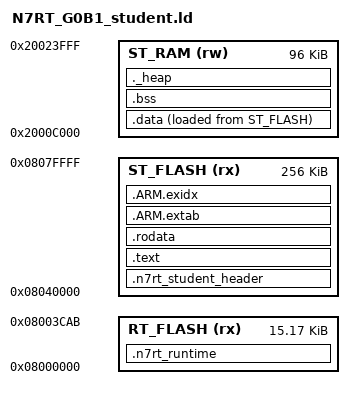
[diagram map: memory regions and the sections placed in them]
/*
 * N7RT student image, STM32G0B1RE. Generated by `stm32lab sdk` (SDK 0.1.0, runtime 0.1.0,
 * ABI 1.0). Do not edit: the runtime reads the student header at 0x08040000 and the student
 * calls the runtime through its API table at 0x08000400 (docs/can-lab-architecture.md 4.2).
 *
 *   RT_FLASH 0x08000000  precompiled runtime, exactly 15532 bytes (SHA-256 202db3fb6e7bc35d...)
 *   ST_FLASH 0x08040000  student header (64 B), student code and constants, 256 KB
 *   ST_RAM   0x2000C000  student .data / .bss / heap (8 KB), SRAM 96 KB
 * The runtime RAM (first 48 KB of SRAM) is not declared: nothing of the student image can be placed there.
 */
ENTRY(n7rt_runtime_reset)            /* 0x080004B1: the runtime Reset_Handler */
EXTERN(n7rt_student_header)

__n7rt_heap_size = 8192;

MEMORY
{
  RT_FLASH (rx) : ORIGIN = 0x08000000, LENGTH = 15532
  ST_FLASH (rx) : ORIGIN = 0x08040000, LENGTH = 256K
  ST_RAM   (rw) : ORIGIN = 0x2000C000, LENGTH = 96K
}

SECTIONS
{
  .n7rt_runtime : { KEEP(*(.n7rt_runtime)) } >RT_FLASH

  .n7rt_student_header : { KEEP(*(.n7rt_student_header)) } >ST_FLASH

  .text :
  {
    . = ALIGN(4);
    *(.text .text.*)
    *(.glue_7) *(.glue_7t) *(.vfp11_veneer) *(.v4_bx) *(.eh_frame)
    . = ALIGN(4);
  } >ST_FLASH

  .rodata :
  {
    . = ALIGN(4);
    *(.rodata .rodata.*)
    KEEP(*(.n7rt_abi_check))
    . = ALIGN(4);
  } >ST_FLASH

  .ARM.extab : { *(.ARM.extab* .gnu.linkonce.armextab.*) } >ST_FLASH
  .ARM.exidx : { *(.ARM.exidx*) } >ST_FLASH

  .data :
  {
    . = ALIGN(4);
    __n7rt_student_data_start = .;
    *(.data .data.*)
    . = ALIGN(4);
    __n7rt_student_data_end = .;
  } >ST_RAM AT>ST_FLASH
  __n7rt_student_data_load = LOADADDR(.data);
  __n7rt_student_image_end = LOADADDR(.data) + SIZEOF(.data);

  .bss (NOLOAD) :
  {
    . = ALIGN(4);
    __n7rt_student_bss_start = .;
    *(.bss .bss.*)
    *(COMMON)
    . = ALIGN(4);
    __n7rt_student_bss_end = .;
  } >ST_RAM

  ._heap (NOLOAD) :
  {
    . = ALIGN(8);
    PROVIDE(end = .);
    PROVIDE(_end = .);
    . = . + __n7rt_heap_size;
  } >ST_RAM
}

ASSERT(DEFINED(n7rt_runtime_v0_1_0), "N7RT: n7rt/lib/n7rt_runtime.o is not runtime 0.1.0: use the linker script shipped with it")
ASSERT(DEFINED(n7rt_runtime_abi_1) && DEFINED(n7rt_glue_abi_1), "N7RT: runtime, glue and linker script do not share ABI 1")
ASSERT(ADDR(.n7rt_runtime) == 0x08000000 && SIZEOF(.n7rt_runtime) == 15532, "N7RT: the runtime image must sit unchanged at 0x08000000 (15532 bytes)")
ASSERT(ADDR(.n7rt_student_header) == 0x08040000 && SIZEOF(.n7rt_student_header) == 64, "N7RT: student header missing or misplaced (n7rt/lib/libn7rt_glue.a)")
ASSERT(__n7rt_student_image_end <= 0x08080000, "N7RT: student image overflows its flash region")
